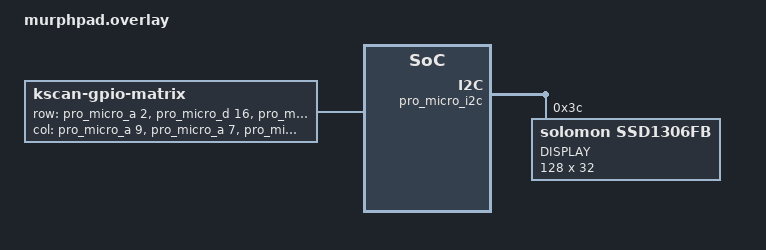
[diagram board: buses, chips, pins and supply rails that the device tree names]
/*
 * Copyright (c) 2021 The ZMK Contributors
 *
 * SPDX-License-Identifier: MIT
 */

#include <dt-bindings/zmk/matrix_transform.h>

/ {
	chosen {
		zmk,kscan = &kscan0;
	};

	kscan0: kscan {
		compatible = "zmk,kscan-gpio-matrix";
		label = "KSCAN";

		diode-direction = "col2row";
		row-gpios
			= <&pro_micro_a 2  (GPIO_ACTIVE_HIGH | GPIO_PULL_DOWN)>
			, <&pro_micro_d 16 (GPIO_ACTIVE_HIGH | GPIO_PULL_DOWN)>
			, <&pro_micro_d 14 (GPIO_ACTIVE_HIGH | GPIO_PULL_DOWN)>
			, <&pro_micro_d 15 (GPIO_ACTIVE_HIGH | GPIO_PULL_DOWN)>
            , <&pro_micro_a 0  (GPIO_ACTIVE_HIGH | GPIO_PULL_DOWN)>
            , <&pro_micro_a 1  (GPIO_ACTIVE_HIGH | GPIO_PULL_DOWN)>
            ;
		col-gpios
			= <&pro_micro_a 9  GPIO_ACTIVE_HIGH>
			, <&pro_micro_a 7  GPIO_ACTIVE_HIGH>
			, <&pro_micro_d 5  GPIO_ACTIVE_HIGH>
			, <&pro_micro_a 6  GPIO_ACTIVE_HIGH>
            , <&pro_micro_a 10 GPIO_ACTIVE_HIGH>
			;
	};

	encoder_1: encoder_1 {
		compatible = "alps,ec11";
		label = "Encoder 1";
		a-gpios = <&pro_micro_d 8 (GPIO_ACTIVE_LOW | GPIO_PULL_UP)>;
		b-gpios = <&pro_micro_d 7 (GPIO_ACTIVE_LOW | GPIO_PULL_UP)>;
		resolution = <4>;
		status = "disabled";
	};
	
	encoder_2: encoder_2 {
		compatible = "alps,ec11";
		label = "Encoder 2";
		a-gpios = <&pro_micro_d 1 (GPIO_ACTIVE_LOW | GPIO_PULL_UP)>;
		b-gpios = <&pro_micro_d 0 (GPIO_ACTIVE_LOW | GPIO_PULL_UP)>;
		resolution = <4>;
		status = "disabled";
	};

};

&pro_micro_i2c {
	status = "okay";

	oled: ssd1306@3c {
		compatible = "solomon,ssd1306fb";
		reg = <0x3c>;
		label = "DISPLAY";
		width = <128>;
		height = <32>;
		segment-offset = <0>;
		page-offset = <0>;
		display-offset = <0>;
		multiplex-ratio = <31>;
		segment-remap;
		com-invdir;
		com-sequential;
		prechargep = <0x22>;
	};
};
